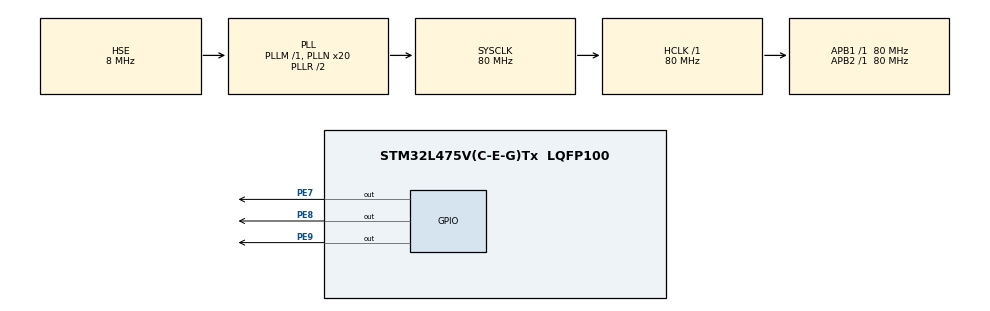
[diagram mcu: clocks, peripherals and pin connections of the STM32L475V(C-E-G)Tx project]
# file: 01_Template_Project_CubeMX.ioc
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Mcu.Family=STM32L4
Mcu.Name=STM32L475V(C-E-G)Tx
Mcu.Package=LQFP100
NVIC.PriorityGroup=NVIC_PRIORITYGROUP_4
PE7.GPIO_ModeDefaultOutputPP=GPIO_MODE_OUTPUT_PP
PE7.GPIO_PuPd=GPIO_PULLUP
PE7.GPIO_Speed=GPIO_SPEED_FREQ_HIGH
PE7.PinState=GPIO_PIN_SET
PE7.Signal=GPIO_Output
PE8.GPIO_PuPd=GPIO_PULLUP
PE8.GPIO_Speed=GPIO_SPEED_FREQ_HIGH
PE8.PinState=GPIO_PIN_SET
PE8.Signal=GPIO_Output
PE9.GPIO_PuPd=GPIO_PULLUP
PE9.GPIO_Speed=GPIO_SPEED_FREQ_HIGH
PE9.PinState=GPIO_PIN_SET
PE9.Signal=GPIO_Output
PH0-OSC_IN\ (PH0).Mode=HSE-External-Oscillator
PH0-OSC_IN\ (PH0).Signal=RCC_OSC_IN
PH1-OSC_OUT\ (PH1).Mode=HSE-External-Oscillator
PH1-OSC_OUT\ (PH1).Signal=RCC_OSC_OUT
ProjectManager.HeapSize=0x200
ProjectManager.StackSize=0x400
ProjectManager.TargetToolchain=MDK-ARM V5
RCC.ADCFreq_Value=32000000
RCC.AHBFreq_Value=80000000
RCC.APB1Freq_Value=80000000
RCC.APB1TimFreq_Value=80000000
RCC.APB2Freq_Value=80000000
RCC.APB2TimFreq_Value=80000000
RCC.CortexFreq_Value=80000000
RCC.HCLKFreq_Value=80000000
RCC.HSE_VALUE=8000000
RCC.HSI_VALUE=16000000
RCC.LSE_VALUE=32768
RCC.MSI_VALUE=4000000
RCC.PLLN=20
RCC.PLLSourceVirtual=RCC_PLLSOURCE_HSE
RCC.SYSCLKFreq_VALUE=80000000
RCC.SYSCLKSource=RCC_SYSCLKSOURCE_PLLCLK
RCC.USBFreq_Value=32000000
RCC.VCOOutputFreq_Value=160000000
board=custom

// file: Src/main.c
/* USER CODE BEGIN Header */
/**
  ******************************************************************************
  * @file           : main.c
  * @brief          : Main program body
  ******************************************************************************
  * @attention
  *
  * <h2><center>&copy; Copyright (c) 2019 STMicroelectronics.
  * All rights reserved.</center></h2>
  *
  * This software component is licensed by ST under BSD 3-Clause license,
  * the "License"; You may not use this file except in compliance with the
  * License. You may obtain a copy of the License at:
  *                        opensource.org/licenses/BSD-3-Clause
  *
  ******************************************************************************
  */
/* USER CODE END Header */

#include "main.h"

void SystemClock_Config(void);
static void MX_GPIO_Init(void);

/* USER CODE BEGIN 0 */
void Delay(__IO uint32_t nCount);
void Delay(__IO uint32_t nCount)
{
    while(nCount--) {};
}
/* USER CODE END 0 */

int main(void)
{

  /* MCU Configuration--------------------------------------------------------*/

  /* Reset of all peripherals, Initializes the Flash interface and the Systick. */
  HAL_Init();

  /* Configure the system clock */
  SystemClock_Config();

  /* Initialize all configured peripherals */
  MX_GPIO_Init();

  /* Infinite loop */
  while (1)
  {

    /* USER CODE BEGIN 3 */
    HAL_GPIO_WritePin(GPIOE, GPIO_PIN_7|GPIO_PIN_8|GPIO_PIN_9, GPIO_PIN_SET);     //PE7 置1
    Delay(0x7FFFFF);
    HAL_GPIO_WritePin(GPIOE, GPIO_PIN_7|GPIO_PIN_8|GPIO_PIN_9, GPIO_PIN_RESET);   //PE7 置0
    Delay(0x7FFFFF);

  }
  /* USER CODE END 3 */
}

void SystemClock_Config(void)
{
  RCC_OscInitTypeDef RCC_OscInitStruct = {0};
  RCC_ClkInitTypeDef RCC_ClkInitStruct = {0};

  /** Initializes the CPU, AHB and APB busses clocks
  */
  RCC_OscInitStruct.OscillatorType = RCC_OSCILLATORTYPE_HSE;
  RCC_OscInitStruct.HSEState = RCC_HSE_ON;
  RCC_OscInitStruct.PLL.PLLState = RCC_PLL_ON;
  RCC_OscInitStruct.PLL.PLLSource = RCC_PLLSOURCE_HSE;
  RCC_OscInitStruct.PLL.PLLM = 1;
  RCC_OscInitStruct.PLL.PLLN = 20;
  RCC_OscInitStruct.PLL.PLLP = RCC_PLLP_DIV7;
  RCC_OscInitStruct.PLL.PLLQ = RCC_PLLQ_DIV2;
  RCC_OscInitStruct.PLL.PLLR = RCC_PLLR_DIV2;
  if (HAL_RCC_OscConfig(&RCC_OscInitStruct) != HAL_OK)
  {
    Error_Handler();
  }
  /** Initializes the CPU, AHB and APB busses clocks
  */
  RCC_ClkInitStruct.ClockType = RCC_CLOCKTYPE_HCLK|RCC_CLOCKTYPE_SYSCLK
                              |RCC_CLOCKTYPE_PCLK1|RCC_CLOCKTYPE_PCLK2;
  RCC_ClkInitStruct.SYSCLKSource = RCC_SYSCLKSOURCE_PLLCLK;
  RCC_ClkInitStruct.AHBCLKDivider = RCC_SYSCLK_DIV1;
  RCC_ClkInitStruct.APB1CLKDivider = RCC_HCLK_DIV1;
  RCC_ClkInitStruct.APB2CLKDivider = RCC_HCLK_DIV1;

  if (HAL_RCC_ClockConfig(&RCC_ClkInitStruct, FLASH_LATENCY_4) != HAL_OK)
  {
    Error_Handler();
  }
  /** Configure the main internal regulator output voltage
  */
  if (HAL_PWREx_ControlVoltageScaling(PWR_REGULATOR_VOLTAGE_SCALE1) != HAL_OK)
  {
    Error_Handler();
  }
}

static void MX_GPIO_Init(void)
{
  GPIO_InitTypeDef GPIO_InitStruct = {0};

  /* GPIO Ports Clock Enable */
  __HAL_RCC_GPIOH_CLK_ENABLE();
  __HAL_RCC_GPIOE_CLK_ENABLE();

  /*Configure GPIO pin Output Level */
  HAL_GPIO_WritePin(GPIOE, GPIO_PIN_7|GPIO_PIN_8|GPIO_PIN_9, GPIO_PIN_SET);

  /*Configure GPIO pins : PE7 PE8 PE9 */
  GPIO_InitStruct.Pin = GPIO_PIN_7|GPIO_PIN_8|GPIO_PIN_9;
  GPIO_InitStruct.Mode = GPIO_MODE_OUTPUT_PP;
  GPIO_InitStruct.Pull = GPIO_PULLUP;
  GPIO_InitStruct.Speed = GPIO_SPEED_FREQ_HIGH;
  HAL_GPIO_Init(GPIOE, &GPIO_InitStruct);

}

void Error_Handler(void)
{
}

/************************ (C) COPYRIGHT STMicroelectronics *****END OF FILE****/
